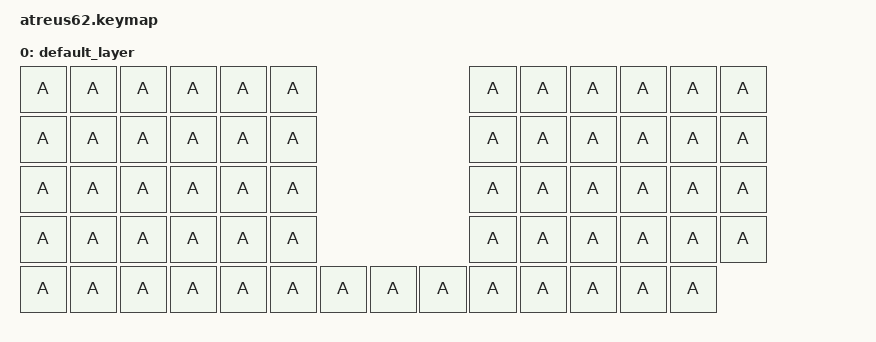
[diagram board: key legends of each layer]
#include <behaviors.dtsi>
#include <dt-bindings/zmk/keys.h>

/ {
    keymap {
        compatible = "zmk,keymap";

        default_layer {
            bindings = 
                &kp A &kp A &kp A &kp A &kp A &kp A                 &kp A &kp A &kp A &kp A &kp A &kp A
                &kp A &kp A &kp A &kp A &kp A &kp A                 &kp A &kp A &kp A &kp A &kp A &kp A
                &kp A &kp A &kp A &kp A &kp A &kp A                 &kp A &kp A &kp A &kp A &kp A &kp A
                &kp A &kp A &kp A &kp A &kp A &kp A                 &kp A &kp A &kp A &kp A &kp A &kp A
                &kp A &kp A &kp A &kp A &kp A &kp A &kp A &kp A &kp A &kp A &kp A &kp A &kp A &kp A
            >;
        };
    };
};
